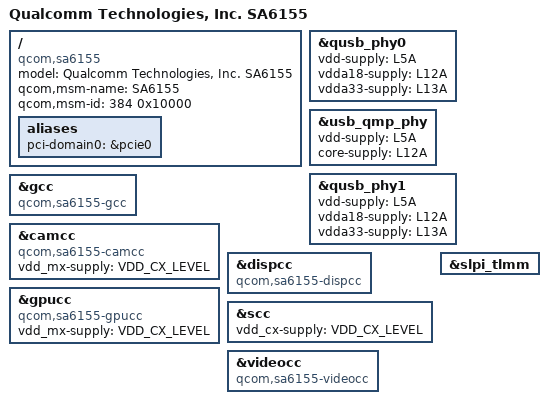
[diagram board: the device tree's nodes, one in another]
#include "sm6150.dtsi"
#include "sa6155-pmic.dtsi"

/ {
	model = "Qualcomm Technologies, Inc. SA6155";
	compatible = "qcom,sa6155";
	qcom,msm-name = "SA6155";
	qcom,msm-id = <384 0x10000>;

	aliases {
		pci-domain0 = &pcie0; /* PCIe0 domain */
	};
};

&qusb_phy0 {
	vdd-supply = <&L5A>;
	vdda18-supply = <&L12A>;
	vdda33-supply = <&L13A>;
};

&usb_qmp_phy {
	vdd-supply = <&L5A>;
	core-supply = <&L12A>;
};

&qusb_phy1 {
	vdd-supply = <&L5A>;
	vdda18-supply = <&L12A>;
	vdda33-supply = <&L13A>;
};

&gcc {
	compatible = "qcom,sa6155-gcc", "syscon";
	/delete-property/ protected-clocks;
};

&camcc {
	compatible = "qcom,sa6155-camcc", "syscon";
	vdd_mx-supply = <&VDD_CX_LEVEL>;
};

&dispcc {
	compatible = "qcom,sa6155-dispcc", "syscon";
};

&gpucc {
	compatible = "qcom,sa6155-gpucc", "syscon";
	vdd_mx-supply = <&VDD_CX_LEVEL>;
};

&scc {
	vdd_cx-supply = <&VDD_CX_LEVEL>;
	status = "ok";
};

&videocc {
	compatible = "qcom,sa6155-videocc", "syscon";
};

#include "sa6155-pcie.dtsi"
&slpi_tlmm {
	status = "ok";
};
